# STM32H523 register map
File version: 1.2
CPU: CM33 r0p0, little endian, MPU, FPU, 4 interrupt priority bits
Registers are 32-bit, read-write, reset 0x0 unless marked. A register's access mark holds for its fields unless they carry their own. Offsets are from the block's base; [hi:lo] are bit positions.

## SPI1 — SPI address block description
Base 0x40013000
Same registers: SPI2 0x40003800, SPI3 0x40003C00, SPI4 0x40014C00, SPI2_S 0x50003800, SPI3_S 0x50003C00, SPI1_S 0x50013000, SPI4_S 0x50014C00
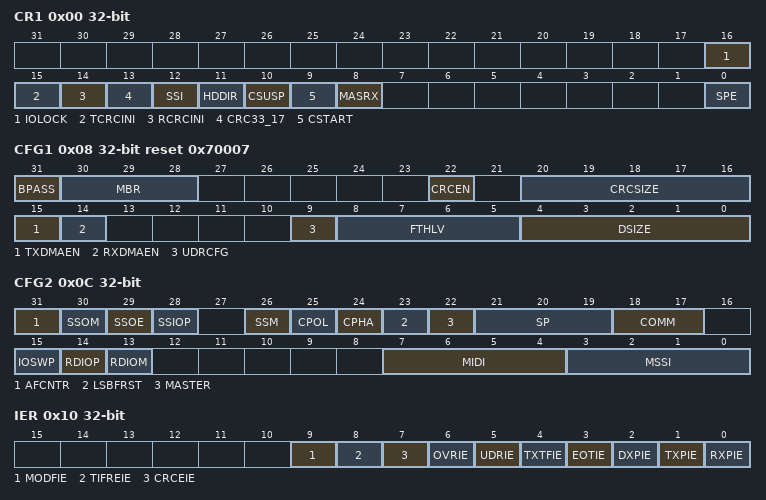
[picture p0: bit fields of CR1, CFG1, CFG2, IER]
0x00 CR1 — SPI/I2S control register 1
  [16] IOLOCK — locking the AF configuration of associated I/Os
    0=Unlocked (IO configuration unlocked); 1=Locked (IO configuration locked)
  [15] TCRCINI — CRC calculation initialization pattern control for transmitter
    0=All zeros TX CRC initialization pattern; 1=All ones TX CRC initialization pattern
  [14] RCRCINI — CRC calculation initialization pattern control for receiver
    0=All zeros RX CRC initialization pattern; 1=All ones RX CRC initialization pattern
  [13] CRC33_17 — 32-bit CRC polynomial configuration
    0=Disabled (Full size (33/17 bit) CRC polynomial is not used); 1=Enabled (Full size (33/17 bit) CRC polynomial is used)
  [12] SSI — internal SS signal input level
    0=SlaveSelected (0 is forced onto the SS signal and the I/O value of the SS pin is ignored); 1=SlaveNotSelected (1 is forced onto the SS signal and the I/O value of the SS pin is ignored)
  [11] HDDIR — Rx/Tx direction at half-duplex mode
    0=Receiver in half duplex mode; 1=Transmitter in half duplex mode
  [10] CSUSP wo — master suspend request
    0=NotRequested (Do not request master suspend); 1=Requested (Request master suspend)
  [9] CSTART — master transfer start
    0=NotStarted (Do not start master transfer); 1=Started (Start master transfer)
  [8] MASRX — master automatic suspension in Receive mode
    0=Disabled (Automatic suspend in master receive-only mode disabled); 1=Enabled (Automatic suspend in master receive-only mode enabled)
  [0] SPE — serial peripheral enable
    0=Disabled (Peripheral disabled); 1=Enabled (Peripheral enabled)
0x04 CR2 — SPI/I2S control register 2
  [15:0] TSIZE — number of data at current transfer
0x08 CFG1 reset 0x70007 — SPI/I2S configuration register 1
  [31] BPASS — bypass of the prescaler at master baud rate clock generator
    0=Disabled (Bypass is disabled); 1=Enabled (Bypass is enabled)
  [30:28] MBR — master baud rate prescaler setting
    0=Div2 (f_spi_ker_ck / 2); 1=Div4 (f_spi_ker_ck / 4); 2=Div8 (f_spi_ker_ck / 8); 3=Div16 (f_spi_ker_ck / 16); 4=Div32 (f_spi_ker_ck / 32); 5=Div64 (f_spi_ker_ck / 64); 6=Div128 (f_spi_ker_ck / 128); 7=Div256 (f_spi_ker_ck / 256)
  [22] CRCEN — hardware CRC computation enable
    0=Disabled (CRC calculation disabled); 1=Enabled (CRC calculation enabled)
  [20:16] CRCSIZE — length of CRC frame to be transacted and compared
  [15] TXDMAEN — Tx DMA stream enable
    0=Disabled (Tx buffer DMA disabled); 1=Enabled (Tx buffer DMA enabled)
  [14] RXDMAEN — Rx DMA stream enable
    0=Disabled (Rx buffer DMA disabled); 1=Enabled (Rx buffer DMA enabled)
  [9] UDRCFG — behavior of slave transmitter at underrun condition
    0=Constant (Slave sends a constant underrun pattern); 1=RepeatReceived (Slave repeats last received data frame from master)
  [8:5] FTHLV — FIFO threshold level
    0=OneFrame (1 frame); 1=TwoFrames (2 frames); 2=ThreeFrames (3 frames); 3=FourFrames (4 frames); 4=FiveFrames (5 frames); 5=SixFrames (6 frames); 6=SevenFrames (7 frames); 7=EightFrames (8 frames); 8=NineFrames (9 frames); 9=TenFrames (10 frames); 10=ElevenFrames (11 frames); 11=TwelveFrames (12 frames); 12=ThirteenFrames (13 frames); 13=FourteenFrames (14 frames); 14=FifteenFrames (15 frames); 15=SixteenFrames (16 frames)
  [4:0] DSIZE — number of bits in a single SPI data frame
0x0C CFG2 — SPI/I2S configuration register 2
  [31] AFCNTR — alternate function GPIOs control
    0=NotControlled (Peripheral takes no control of GPIOs while disabled); 1=Controlled (Peripheral controls GPIOs while disabled)
  [30] SSOM — SS output management in master mode
    0=Asserted (SS is asserted until data transfer complete); 1=NotAsserted (Data frames interleaved with SS not asserted during MIDI)
  [29] SSOE — SS output enable
    0=Disabled (SS output is disabled in master mode); 1=Enabled (SS output is enabled in master mode)
  [28] SSIOP — SS input/output polarity
    0=ActiveLow (Low level is active for SS signal); 1=ActiveHigh (High level is active for SS signal)
  [26] SSM — software management of SS signal input
    0=Disabled (Software slave management disabled); 1=Enabled (Software slave management enabled)
  [25] CPOL — clock polarity
    0=IdleLow (CK to 0 when idle); 1=IdleHigh (CK to 1 when idle)
  [24] CPHA — clock phase
    0=FirstEdge (The first clock transition is the first data capture edge); 1=SecondEdge (The second clock transition is the first data capture edge)
  [23] LSBFRST — data frame format
    0=MSBFirst (Data is transmitted/received with the MSB first); 1=LSBFirst (Data is transmitted/received with the LSB first)
  [22] MASTER — SPI master
    0=Slave configuration; 1=Master configuration
  [21:19] SP — serial protocol
    0=Motorola SPI protocol; 1=TI (TI SPI protocol)
  [18:17] COMM — SPI Communication Mode
    0=FullDuplex; 1=Transmitter (Simplex transmitter only); 2=Receiver (Simplex receiver only); 3=HalfDuplex
  [15] IOSWP — swap functionality of MISO and MOSI pins
    0=Disabled (MISO and MOSI not swapped); 1=Enabled (MISO and MOSI swapped)
  [14] RDIOP — RDY signal input/output polarity
    0=high level of the signal means the slave is ready for communication; 1=Low (low level of the signal means the slave is ready for communication)
  [13] RDIOM — RDY signal input/output management
    0=Active (RDY signal is defined internally fixed as permanently active (RDIOP setting has no effect)); 1=Pin (RDY signal is overtaken from alternate function input (at master case) or output (at slave case) of the dedicated pin (RDIOP setting takes effect))
  [7:4] MIDI — master Inter-Data Idleness
  [3:0] MSSI — Master SS Idleness
0x10 IER — SPI/I2S interrupt enable register
  [all] fields
    0=Disabled (Interrupt disabled); 1=Enabled (Interrupt enabled)
  [9] MODFIE — mode Fault interrupt enable
  [8] TIFREIE — TIFRE interrupt enable
  [7] CRCEIE — CRC error interrupt enable
  [6] OVRIE — OVR interrupt enable
  [5] UDRIE — UDR interrupt enable
  [4] TXTFIE — TXTFIE interrupt enable
  [3] EOTIE — EOT, SUSP and TXC interrupt enable
  [2] DXPIE — DXP interrupt enabled
  [1] TXPIE — TXP interrupt enable
  [0] RXPIE — RXP interrupt enable
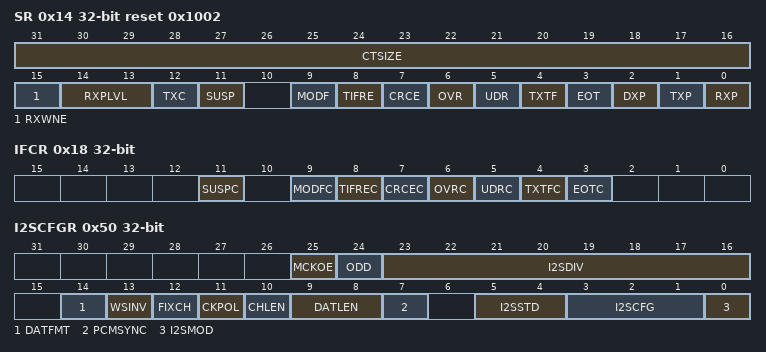
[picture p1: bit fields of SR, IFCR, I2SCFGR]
0x14 SR ro reset 0x1002 — SPI/I2S status register
  [31:16] CTSIZE — number of data frames remaining in current TSIZE session
  [15] RXWNE — RxFIFO word not empty
    0=Less than 32-bit data frame received; 1=At least 32-bit data frame received
  [14:13] RXPLVL — RxFIFO packing level
    0=Zero frames beyond packing ratio available; 1=One frame beyond packing ratio available; 2=TwoFrames (Two frame beyond packing ratio available); 3=ThreeFrames (Three frame beyond packing ratio available)
  [12] TXC — TxFIFO transmission complete
    0=Ongoing (Transmission ongoing); 1=Completed (Transmission completed)
  [11] SUSP — suspension status
    0=NotSuspended (Master not suspended); 1=Suspended (Master suspended)
  [9] MODF — mode fault
    0=NoFault (No mode fault detected); 1=Fault (Mode fault detected)
  [8] TIFRE — TI frame format error
    0=NoError (TI frame format error detected); 1=Error (TI frame format error detected)
  [7] CRCE — CRC error
    0=NoError (No CRC error detected); 1=Error (CRC error detected)
  [6] OVR — overrun
    0=No overrun occurred; 1=Overrun occurred
  [5] UDR — underrun
    0=No underrun occurred; 1=Underrun occurred
  [4] TXTF — transmission transfer filled
    0=NotCompleted (Transmission buffer incomplete); 1=Completed (Transmission buffer filled with at least one transfer)
  [3] EOT — end of transfer
    0=NotCompleted (Transfer ongoing or not started); 1=Completed (Transfer complete)
  [2] DXP — duplex packet
    0=Unavailable (Duplex packet unavailable: no space for transmission and/or no data received); 1=Available (Duplex packet available: space for transmission and data received)
  [1] TXP — Tx-packet space available
    0=Full (Tx buffer full); 1=NotFull (Tx buffer not full)
  [0] RXP — Rx-packet available
    0=Empty (Rx buffer empty); 1=NotEmpty (Rx buffer not empty)
0x18 IFCR wo — SPI/I2S interrupt/status flags clear register
  [all] fields
    1=Clear interrupt flag
  [11] SUSPC write-1-clears — Suspend flag clear
  [9] MODFC write-1-clears — mode fault flag clear
  [8] TIFREC write-1-clears — TI frame format error flag clear
  [7] CRCEC write-1-clears — CRC error flag clear
  [6] OVRC write-1-clears — overrun flag clear
  [5] UDRC write-1-clears — underrun flag clear
  [4] TXTFC write-1-clears — transmission transfer filled flag clear
  [3] EOTC write-1-clears — end of transfer flag clear
0x20 TXDR wo — /I2SSPI/I2S transmit data register
  [31:0] TXDR — transmit data register
0x20 TXDR16 16-bit wo reset not defined (alternate view of TXDR) — Direct 16-bit access to transmit data register
  [15:0] TXDR — Transmit data register
0x20 TXDR8 8-bit wo reset not defined (alternate view of TXDR) — Direct 8-bit access to transmit data register
  [7:0] TXDR — Transmit data register
0x30 RXDR ro — SPI/I2S receive data register
  [31:0] RXDR — receive data register
0x30 RXDR16 16-bit ro reset not defined (alternate view of RXDR) — Direct 16-bit access to receive data register
  [15:0] RXDR — Receive data register
0x30 RXDR8 8-bit ro reset not defined (alternate view of RXDR) — Direct 8-bit access to receive data register
  [7:0] RXDR — Receive data register
0x40 CRCPOLY reset 0x107 — SPI/I2S polynomial register
  [31:0] CRCPOLY — CRC polynomial register
0x44 TXCRC ro — SPI/I2S transmitter CRC register
  [31:0] TXCRC — CRC register for transmitter
0x48 RXCRC ro — SPI/I2S receiver CRC register
  [31:0] RXCRC — CRC register for receiver
0x4C UDRDR — SPI underrun data register
  [31:0] UDRDR — data at slave underrun condition
0x50 I2SCFGR — SPI/I2S configuration register
  [25] MCKOE — master clock output enable
    0=Disabled (Master clock output disabled); 1=Enabled (Master clock output enabled)
  [24] ODD — odd factor for the prescaler
    0=Even (Real divider value is I2SDIV*2); 1=Odd (Real divider value is I2SDIV*2 + 1)
  [23:16] I2SDIV — Iless thansup>2less than/sup>S linear prescaler
  [14] DATFMT — data format
    0=RightAligned (The data inside RXDR and TXDR are right aligned); 1=LeftAligned (The data inside RXDR and TXDR are left aligned)
  [13] WSINV — word select inversion
    0=Disabled (Word select inversion disabled); 1=Enabled (Word select inversion enabled)
  [12] FIXCH — fixed channel length in slave
    0=NotFixed (The channel length in slave mode is different from 16 or 32 bits (CHLEN not taken into account)); 1=Fixed (The channel length in slave mode is supposed to be 16 or 32 bits (according to CHLEN))
  [11] CKPOL — serial audio clock polarity
    0=SampleOnRising (Signals are sampled on rising and changed on falling clock edges); 1=SampleOnFalling (Signals are sampled on falling and changed on rising clock edges)
  [10] CHLEN — channel length (number of bits per audio channel)
    0=Bits16 (16 bit per channel); 1=Bits32 (32 bit per channel)
  [9:8] DATLEN — data length to be transferred.
    0=Bits16 (16 bit data length); 1=Bits24 (24 bit data length); 2=Bits32 (32 bit data length)
  [7] PCMSYNC — PCM frame synchronization
    0=Short PCM frame synchronization; 1=Long PCM frame synchronization
  [5:4] I2SSTD — Iless thansup>2less than/sup>S standard selection
    0=Philips (I2S Philips standard); 1=LeftAligned (MSB/left justified standard); 2=RightAligned (LSB/right justified standard); 3=PCM (PCM standard)
  [3:1] I2SCFG — I2S configuration mode
    0=SlaveTransmit; 1=SlaveReceive (Slave, recteive); 2=MasterTransmit; 3=MasterReceive; 4=SlaveFullDuplex; 5=MasterFullDuplex
  [0] I2SMOD — I2S mode selection
    0=SPI (SPI mode selected); 1=I2S (I2S/PCM mode selected)
